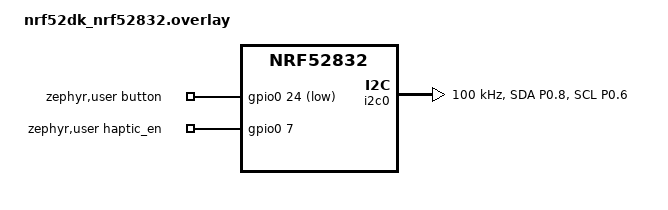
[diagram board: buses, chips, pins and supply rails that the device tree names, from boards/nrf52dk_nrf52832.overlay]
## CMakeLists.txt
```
cmake_minimum_required(VERSION 3.20.0)

list(APPEND BOARD_ROOT ${CMAKE_CURRENT_SOURCE_DIR})

# Inicialize Zephyr build system
find_package(Zephyr REQUIRED HINTS $ENV{ZEPHYR_BASE})

# Project name and version
project(
    joya_phone_connection_fw
    VERSION 2.0
    DESCRIPTION "Firmware for Joya controller with modular architecture"
)

# Source files for the application
target_sources(app PRIVATE 
    src/main.c
    src/app_comm.c
    src/app_state.c
    src/ble_driver.c
    src/ota_access.c
    src/test_image_guard.c
    src/button.c
    src/haptics.c
    src/flash_memory.c
    src/emergency_phase.c
    src/diagnostics.c
    src/battery.c
    src/wdt_guard.c
    src/fatal_recovery.c
)

target_sources_ifdef(CONFIG_JOYA_HAPTICS_TEST_INDICATOR app PRIVATE
    src/haptics_test_indicator.c
)

# Include directories for the application
target_include_directories(app PRIVATE include)
```

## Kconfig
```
mainmenu "Joya firmware"

source "Kconfig.zephyr"

config JOYA_HAPTICS_TEST_INDICATOR
	bool "Show allowed haptic requests on nRF52 DK LED0"
	default n
	depends on BOARD_NRF52DK_NRF52832 && GPIO
	help
	  Diagnostic only. Pulse LED0 when battery policy allows a haptic
	  request, regardless of whether the physical DRV2605 is present.
```

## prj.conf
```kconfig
# ==================================================
# GPIO CORE
# ==================================================
CONFIG_GPIO=y
CONFIG_ADC=y

# ==================================================
# I2C CORE
# ==================================================
CONFIG_I2C=y

# ==================================================
# LOGGING / CONSOLE DISABLED
# ==================================================
CONFIG_LOG=n
CONFIG_PRINTK=n
CONFIG_CONSOLE=n
CONFIG_EARLY_CONSOLE=n
CONFIG_BOOT_BANNER=n

CONFIG_UART_CONSOLE=n
CONFIG_RTT_CONSOLE=n

CONFIG_LOG_BACKEND_RTT=n
CONFIG_LOG_BACKEND_UART=n

# ==================================================
# MANUAL SEGGER RTT DEBUG ONLY
# ==================================================
CONFIG_USE_SEGGER_RTT=n
CONFIG_SEGGER_RTT_MODE_NO_BLOCK_SKIP=n
CONFIG_SEGGER_RTT_INIT_MODE_ALWAYS=n

# ==================================================
# Stacks
# ==================================================
CONFIG_MAIN_STACK_SIZE=4096
CONFIG_SYSTEM_WORKQUEUE_STACK_SIZE=4096


# ==================================================
# BLUETOOTH CORE
# ==================================================
CONFIG_BT=y
CONFIG_BT_PERIPHERAL=y

# Nombre base por defecto
CONFIG_BT_DEVICE_NAME="Joya"

# Habilitar la capacidad de cambiar el nombre dinámicamente
CONFIG_BT_DEVICE_NAME_DYNAMIC=y
CONFIG_BT_DEVICE_NAME_MAX=32

CONFIG_BT_MAX_CONN=1
CONFIG_BT_GATT_DYNAMIC_DB=y

# For debug
CONFIG_BT_GAP_PERIPHERAL_PREF_PARAMS=y
CONFIG_BT_PERIPHERAL_PREF_MIN_INT=36      
# 45 ms - apple pide >= 15 ms, < 2 s (unidades de 1.25 ms)
CONFIG_BT_PERIPHERAL_PREF_MAX_INT=72      
# 90 ms - apple pide <= 2 segundos
CONFIG_BT_PERIPHERAL_PREF_LATENCY=4       
# apple pide <= 30
CONFIG_BT_PERIPHERAL_PREF_TIMEOUT=600     
# 6 s - apple pide entre 6 y 18 segundos (unidades de 10 ms)

# ==================================================
# FOR FLASH STORAGE
# ==================================================
CONFIG_FLASH=y
CONFIG_FLASH_MAP=y
CONFIG_FLASH_PAGE_LAYOUT=y
CONFIG_NVS=y

CONFIG_SETTINGS=y
CONFIG_SETTINGS_NVS=y

#CONFIG_ARM_MPU=y
CONFIG_MPU_ALLOW_FLASH_WRITE=y

# Hardware watchdog: one RR channel, active during sleep, paused by a debugger.
CONFIG_WATCHDOG=y
CONFIG_WDT_NRFX_NO_IRQ=y

# Route controller assertions through the application's fatal reset handler.
CONFIG_BT_CTLR_ASSERT_HANDLER=y

# ==================================================
# MCUboot / OTA por Bluetooth
# ==================================================
CONFIG_BOOTLOADER_MCUBOOT=y

CONFIG_FLASH=y
CONFIG_FLASH_MAP=y
CONFIG_STREAM_FLASH=y
CONFIG_IMG_MANAGER=y

CONFIG_NET_BUF=y
CONFIG_ZCBOR=y
CONFIG_CRC=y

CONFIG_MCUMGR=y
CONFIG_MCUMGR_GRP_IMG=y
CONFIG_MCUMGR_GRP_OS=y
CONFIG_MCUMGR_TRANSPORT_BT=y
CONFIG_MCUMGR_TRANSPORT_BT_DYNAMIC_SVC_REGISTRATION=y
CONFIG_MCUMGR_MGMT_NOTIFICATION_HOOKS=y
CONFIG_MCUMGR_GRP_IMG_UPLOAD_CHECK_HOOK=y
CONFIG_MCUMGR_GRP_IMG_STATUS_HOOKS=y
CONFIG_MCUMGR_GRP_IMG_SLOT_INFO=y

#CONFIG_LOG=y
#CONFIG_MCUMGR_GRP_IMG_LOG_LEVEL_DBG=y

#CONFIG_USE_SEGGER_RTT=y
#CONFIG_LOG_BACKEND_RTT=y

CONFIG_BT_L2CAP_TX_MTU=247
CONFIG_BT_BUF_ACL_RX_SIZE=251
CONFIG_BT_BUF_ACL_TX_SIZE=251
CONFIG_BT_CTLR_DATA_LENGTH_MAX=251
CONFIG_BT_BUF_ACL_TX_COUNT=3

# Test with internal RC
CONFIG_CLOCK_CONTROL_NRF_K32SRC_RC=y
CONFIG_CLOCK_CONTROL_NRF_K32SRC_XTAL=n
CONFIG_CLOCK_CONTROL_NRF_K32SRC_500PPM=y

# Power
CONFIG_PM_DEVICE=y

# ===== Soporte iBeacons
CONFIG_BT_EXT_ADV=y
CONFIG_BT_EXT_ADV_MAX_ADV_SET=2
```

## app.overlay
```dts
#include <zephyr/dt-bindings/gpio/gpio.h>
#include <zephyr/dt-bindings/i2c/i2c.h>
#include <zephyr/dt-bindings/pinctrl/nrf-pinctrl.h>

/ {
	zephyr,user {
		button_gpios = <&gpio0 24 (GPIO_PULL_UP | GPIO_ACTIVE_LOW)>;
		haptic_en_gpios = <&gpio0 7 GPIO_ACTIVE_HIGH>;
	};
};

&pinctrl {
	i2c0_default: i2c0_default {
		group1 {
			psels = <NRF_PSEL(TWIM_SDA, 0, 8)>,
				<NRF_PSEL(TWIM_SCL, 0, 6)>;
		};
	};

	i2c0_sleep: i2c0_sleep {
		group1 {
			psels = <NRF_PSEL(TWIM_SDA, 0, 8)>,
				<NRF_PSEL(TWIM_SCL, 0, 6)>;
			low-power-enable;
		};
	};
};

&i2c0 {
	status = "okay";
	clock-frequency = <I2C_BITRATE_STANDARD>;
	pinctrl-0 = <&i2c0_default>;
	pinctrl-1 = <&i2c0_sleep>;
	pinctrl-names = "default", "sleep";
};

&uart0 {
	status = "disabled";
};
```

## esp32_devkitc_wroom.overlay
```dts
/ {
    aliases {
        boton-emergencia = &boton_esp;
    };

    /* Define button node */
    botones_joya {
        compatible = "gpio-keys";

        boton_esp: boton_0 {
            gpios = <&gpio0 0 (GPIO_PULL_UP | GPIO_ACTIVE_LOW)>;
            label = "Test Button ESP32";
        };
    };

    /* For printk */
    chosen {
        zephyr,console = &uart0;
        zephyr,shell-uart = &uart0;
    };
};

/* Serial port 0 - 115200 */
&uart0 {
    status = "okay";
    current-speed = <115200>;
};
```

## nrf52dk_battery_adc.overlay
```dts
/* Test fixture: connect the battery divider output to DK A5 / P0.31.
 * The firmware expects the same 120k/82k divider used by Joya.
 */
#include <zephyr/dt-bindings/adc/adc.h>
#include <zephyr/dt-bindings/adc/nrf-adc.h>

/ {
	zephyr,user {
		io-channels = <&adc 0>;
		io-channel-names = "battery";
	};
};

&adc {
	status = "okay";
	#address-cells = <1>;
	#size-cells = <0>;

	channel@0 {
		reg = <0>;
		zephyr,gain = "ADC_GAIN_1_3";
		zephyr,reference = "ADC_REF_INTERNAL";
		zephyr,acquisition-time = <ADC_ACQ_TIME(ADC_ACQ_TIME_MICROSECONDS, 40)>;
		zephyr,input-positive = <NRF_SAADC_AIN7>;
		zephyr,resolution = <12>;
	};
};
```

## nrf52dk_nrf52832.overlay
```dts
#include <zephyr/dt-bindings/gpio/gpio.h>
#include <zephyr/dt-bindings/i2c/i2c.h>
#include <zephyr/dt-bindings/pinctrl/nrf-pinctrl.h>

/ {
	/*
 	* NOTE:
 	* This configuration uses the nRF52 DK user button (P0.13).
 	* When running on the target hardware, replace the GPIO
 	* below with the pin connected to the emergency button.
 	*/

	joya_buttons {
		compatible = "gpio-keys";

		emergency_button: emergency_button {
			gpios = <&gpio0 14 (GPIO_PULL_UP | GPIO_ACTIVE_LOW)>;
			label = "Joya emergency button";
			zephyr,code = <INPUT_KEY_0>;
		};
	};

	zephyr,user {
		haptic_en_gpios = <&gpio0 7 GPIO_ACTIVE_HIGH>;
	};

	aliases {
		boton-emergencia = &emergency_button;
	};
};

&pinctrl {
	i2c0_default: i2c0_default {
		group1 {
			psels = <NRF_PSEL(TWIM_SDA, 0, 8)>,
				<NRF_PSEL(TWIM_SCL, 0, 6)>;
		};
	};

	i2c0_sleep: i2c0_sleep {
		group1 {
			psels = <NRF_PSEL(TWIM_SDA, 0, 8)>,
				<NRF_PSEL(TWIM_SCL, 0, 6)>;
			low-power-enable;
		};
	};
};

&i2c0 {
	status = "okay";
	clock-frequency = <I2C_BITRATE_STANDARD>;
	pinctrl-0 = <&i2c0_default>;
	pinctrl-1 = <&i2c0_sleep>;
	pinctrl-names = "default", "sleep";
};

&uart0 {
	status = "disabled";
};

&uicr {
    /delete-property/ gpio-as-nreset;
};
```

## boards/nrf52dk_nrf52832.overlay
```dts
#include <zephyr/dt-bindings/gpio/gpio.h>
#include <zephyr/dt-bindings/i2c/i2c.h>
#include <zephyr/dt-bindings/pinctrl/nrf-pinctrl.h>

/ {
	zephyr,user {
		button-gpios = <&gpio0 24 (GPIO_PULL_UP | GPIO_ACTIVE_LOW)>;
		haptic_en-gpios = <&gpio0 7 GPIO_ACTIVE_HIGH>;
	};
};

&pinctrl {
	i2c0_default: i2c0_default {
		group1 {
			psels = <NRF_PSEL(TWIM_SDA, 0, 8)>,
				<NRF_PSEL(TWIM_SCL, 0, 6)>;
		};
	};

	i2c0_sleep: i2c0_sleep {
		group1 {
			psels = <NRF_PSEL(TWIM_SDA, 0, 8)>,
				<NRF_PSEL(TWIM_SCL, 0, 6)>;
			low-power-enable;
		};
	};
};

&i2c0 {
	status = "okay";
	clock-frequency = <I2C_BITRATE_STANDARD>;
	pinctrl-0 = <&i2c0_default>;
	pinctrl-1 = <&i2c0_sleep>;
	pinctrl-names = "default", "sleep";

	/* (to do) add haptic driver */
};

&uart0 {
	status = "disabled";
};

// Just for solve the warning of using GPIO0_24
&spi2 {
        status = "disabled";
};
```

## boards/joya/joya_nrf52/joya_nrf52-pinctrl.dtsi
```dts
#include <zephyr/dt-bindings/pinctrl/nrf-pinctrl.h>

&pinctrl {
	i2c0_default: i2c0_default {
		group1 {
			psels = <NRF_PSEL(TWIM_SDA, 0, 8)>,
				<NRF_PSEL(TWIM_SCL, 0, 6)>;

			// Remove internal pull-up resistor
		};
	};

	i2c0_sleep: i2c0_sleep {
		group1 {
			psels = <NRF_PSEL(TWIM_SDA, 0, 8)>,
				<NRF_PSEL(TWIM_SCL, 0, 6)>;
			low-power-enable;
		};
	};
};
```

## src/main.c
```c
#include <zephyr/kernel.h>
#include <zephyr/dfu/mcuboot.h>
#include <zephyr/sys/reboot.h>
#include "button.h"
#include "app_state.h"
#include "battery.h"
#include "test_image_guard.h"
#include "diagnostics.h"
#include "wdt_guard.h"

int main(void) {
    bool watchdog_active = wdt_guard_init();
    bool ota_test_boot = !boot_is_img_confirmed();

    int ret ;
    ret = storage_init();
    diagnostics_record_init(DIAG_INIT_SETTINGS, ret);
    if (ret != 0) {
        // Storage initialization failed - continuing with RAM defaults
    }
    
    if (ota_test_boot) {
        /* A Test image must prove the recovery button and BLE setup path work. */
        test_image_guard_init();
        ret = button_init();
        diagnostics_record_init(DIAG_INIT_BUTTON, ret);
        if (ret != 0) {
            sys_reboot(SYS_REBOOT_COLD);
        }
        ret = ble_driver_init();
        diagnostics_record_init(DIAG_INIT_BLE, ret);
        if (ret != 0) {
            sys_reboot(SYS_REBOOT_COLD);
        }
        ret = app_start_test_setup();
        if (ret != 0) {
            sys_reboot(SYS_REBOOT_COLD);
        }
        test_image_guard_start();
    } else {
        ret = ble_driver_init();
        diagnostics_record_init(DIAG_INIT_BLE, ret);
        if (ret != 0) {
            /* The guard never feeds before main_ready. With WDT running,
             * sleep until its hardware reset; otherwise retry after a delay.
             */
            if (!watchdog_active) {
                k_sleep(K_SECONDS(30));
                sys_reboot(SYS_REBOOT_COLD);
            }
            k_sleep(K_FOREVER);
        }
        ret = button_init();
        diagnostics_record_init(DIAG_INIT_BUTTON, ret);
        if (ret != 0) {
            /* BLE is initialized; continue without button gestures. */
        }
    }


    ret = haptics_init();
    diagnostics_record_init(DIAG_INIT_HAPTIC, ret);
    if (ret < 0) {
        // LOG: Haptics initialization failed - continuing without haptics
        // (improvement): decide what to do if haptics initialization fails (e.g., retry, log error, etc.)
    } 
    
    /*else {
         * Non-blocking startup check. If the haptic controller was detected,
         * schedule one short existing pattern without delaying BLE or OTA.
         
        haptics_play(HAPTICS_PATTERN_ACK_CONNECTION);
    }
    */

    ret = battery_init();
    if (ret == 0) {
        ret = battery_monitor_start();
    }
    diagnostics_record_init(DIAG_INIT_BATTERY, ret);
    diagnostics_finish_init();
    wdt_guard_main_ready();
    
    // LOG: Initialization complete


    // Keep the main thread alive
    k_sleep(K_FOREVER);
}
```

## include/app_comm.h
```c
#ifndef APP_COMM_H
#define APP_COMM_H

#include <stdint.h>
#include <stddef.h>
#include <sys/types.h>
#include <zephyr/bluetooth/conn.h>
#include <zephyr/bluetooth/gatt.h>
#include "app_state.h"

/**
 * @brief Save the received application identifier.
 * @return 0 on success, non-zero on failure.
 */
int save_received_app_id(const uint8_t *received_app_id);

/**
 * @brief Compare the saved application identifier with the received identifier.
 * @param saved_app_id Pointer to the saved application identifier to compare.
 * @return 0 if the identifiers match, or a non-zero value otherwise.
 */
int check_app_id(const uint8_t *received_app_id, const uint8_t *saved_app_id);

/**
 * @brief Handle writes to the RX characteristic.
 * @param conn The Bluetooth connection.
 * @param attr The GATT attribute.
 * @param buf Buffer containing the received data.
 * @param len Length of the received data.
 * @param offset Offset of the received data.
 * @param flags Write flags.
 * @return The number of bytes processed, or a GATT error.
 */
ssize_t on_rx_write_handler(struct bt_conn *conn, const struct bt_gatt_attr *attr, const void *buf, uint16_t len, uint16_t offset, uint8_t flags);

/**
 * @brief Handle BLE connection events.
 * @param conn The Bluetooth connection.
 * @param err Connection error code.
 */
void on_connected_handler(struct bt_conn *conn, uint8_t err);

/**
 * @brief Handle BLE disconnection events.
 * @param conn The Bluetooth connection.
 * @param reason Disconnection reason code.
 */
void on_disconnected_handler(struct bt_conn *conn, uint8_t reason);

/**
 * @brief Handle writes to the RX authentication characteristic.
 * @param conn The Bluetooth connection.
 * @param attr The GATT attribute.
 * @param buf Buffer containing the received application identifier.
 * @param len Length of the received data.
 * @param offset Offset of the received data.
 * @param flags Write flags.
 * @return The number of bytes processed, or a GATT error.
 */
ssize_t on_rx_auth_write_handler(struct bt_conn *conn, const struct bt_gatt_attr *attr, const void *buf, uint16_t len, uint16_t offset, uint8_t flags);

/** @brief Application command enumeration. 
*/
enum {
    INIT_JOYA_COMMAND = 0x01,
    COMMAND_ROUTINE = 0x02,
    COMMAND_END_ROUTINE = 0x03,
    COMMAND_EMERGENCY = 0x04,
    COMMAND_ACK = 0x05,
    COMMAND_NACK = 0x06,
    LOW_BATTERY_LEVEL_1 = 0x07,
    LOW_BATTERY_LEVEL_2 = 0x08,
    BATTERY_NORMAL = 0x09,
    END_JOYA_COMMAND = 0x0A,

    INIT_APP_COMMAND = 0x40,
    COMMAND_ACK_EMERGENCY = 0x41,
    COMMAND_STOP_EMERGENCY = 0x42,
    COMMAND_FOLLOW_ME = 0x43,
    COMMAND_FRIEND_EMERGENCY = 0x44,
    COMMAND_FRIEND_STOP_EMERGENCY = 0x45,
    END_APP_COMMAND = 0x46,
    COMMAND_OTA_ENABLE = 0x70,
    COMMAND_OTA_DISABLE = 0x71,
};

#endif
```

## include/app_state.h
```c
#ifndef APP_STATE_H
#define APP_STATE_H

#define SIZE_APP_ID 16

#include "ble_driver.h"
#include "app_comm.h"
#include "flash_memory.h"
#include "haptics.h"

#include <stdbool.h>
#include <stdint.h>
#include <zephyr/kernel.h>

#define EMERGENCY_RETRY_INITIAL_MS 1000
#define EMERGENCY_RETRY_FAST_MS 2000
#define EMERGENCY_RETRY_MEDIUM_MS 5000
#define EMERGENCY_RETRY_SLOW_MS 10000
#define EMERGENCY_RETRY_VERY_SLOW_MS 30000

#define BLE_SETUP_TIMEOUT_MS 90000

typedef enum {
    STATE_UNPAIRED,
    STATE_SETUP_MODE,
    STATE_SETUP_WAITING_IDENTIFIER,
    STATE_SETUP_WAITING_NEW_IDENTIFIER,
    STATE_WAITING_NOTIFICATION_ENABLE,
    STATE_BONDED_DISCONNECTED,
    STATE_AUTHENTICATED,
    STATE_EMERGENCY
} app_state_t;

typedef enum {
    // BUTTON EVENTS
    EV_BTN_1_PULSE,
    EV_BTN_2_PULSE,
    EV_BTN_LONG_PRESS,  
    EV_BTN_FACTORY_THRESHOLD,
    EV_BTN_SUSPEND_REQUEST,
    EV_BTN_EMERGENCY,   
    EV_BTN_FACTORY_RESET,
    EV_BOOT_TEST_SETUP_REQUEST,

    // JOYA EVENTS
    EV_APP_IDENTIFIER_RECEIVED,
    EV_EMERGENCY_RETRY,
    EV_BATTERY_LEVEL_1,
    EV_BATTERY_LEVEL_2,
    EV_BATTERY_NORMAL,
    EV_BATTERY_RECHECK_DONE,
    EV_CRITICAL_WINDOW_TIMEOUT,
    
    // CONNECTION EVENTS
    EV_BLE_CONNECTED,
    EV_BLE_DISCONNECTED,
    EV_BLE_TIMEOUT,
    EV_BLE_RESTART_ADVERTISING,
    EV_BLE_NOTIFY_ENABLED,
    EV_BLE_BATTERY_NOTIFY_ENABLED,
    EV_AUTH_DELIVERY_RETRY,

    // APPLICATION EVENTS
    EV_APP_STOP_EMERGENCY,     
    EV_APP_FOLLOW_ME,
    EV_APP_ACK_EMERGENCY,
    EV_APP_FRIEND_EMERGENCY,
    EV_APP_OTA_ENABLE,
    EV_APP_OTA_DISABLE,
    EV_OTA_UPDATE_STOPPED,
    EV_HAPTICS_SUSPEND_DONE,
    EV_HAPTICS_FACTORY_DONE
} event_type_t;

typedef struct {
    event_type_t type;
    struct bt_conn *conn;
    uint8_t app_id[SIZE_APP_ID];
} app_event_t;

/**
 * @brief Process an application event.
 * @param event The event to process.
 */
void process_event(const app_event_t *entry);

/**
 * @brief Run the finite state machine thread loop.
 * This function initializes the work structures and enters the main event loop.
 */
void fsm_thread_loop(void);

/**
 * @brief Add an event to the event queue.
 * @param event The event to add.
 * @return 0 on success, or a negative error code on failure.
 */
int add_event(event_type_t event);
int add_event_for_conn(event_type_t event, struct bt_conn *conn, const uint8_t *app_id);

/** Number of events waiting for the FSM thread. */
unsigned int app_state_pending_events(void);

/**
 * @brief Get the current application state.
 * @return The current application state.
 */
app_state_t get_current_state(void);

/** Start Setup Mode from the FSM for an MCUboot Test image and report advertising status. */
int app_start_test_setup(void);

#endif // APP_STATE_H
```

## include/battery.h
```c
#ifndef JOYA_BATTERY_H_
#define JOYA_BATTERY_H_

#include <stdint.h>

#define BATTERY_MONITOR_INTERVAL_MS     60000
#define BATTERY_VERIFY_INTERVAL_MS      10000
#define BATTERY_VERIFY_SAMPLES          6
#define BATTERY_VERIFY_MIN_VOTES        5
#define BATTERY_RECHECK_INTERVAL_MS     1000

#define BATTERY_LEVEL_1_MV              3000//3500
#define BATTERY_LEVEL_2_MV              2900//3400

/* Para recuperarse, cada umbral exige superar su valor por este margen. */
#define BATTERY_HYSTERESIS_MV           50

/* Inicializar el canal SAADC antes de leer o iniciar el monitoreo. */
int battery_init(void);

/* Leer VBAT en milivoltios. Esta llamada espera a que termine una conversión. */
int battery_get_voltage_mv(int32_t *voltage_mv);

/* Programar la primera medición de inmediato y luego cada intervalo. */
int battery_monitor_start(void);
int battery_monitor_stop(void);

/* Devuelve -ENODATA hasta la primera medición periódica exitosa. */
int battery_get_last_voltage_mv(int32_t *voltage_mv);

/* Request six fresh ADC samples; completion arrives as EV_BATTERY_RECHECK_DONE. */
int battery_request_recheck(void);
/* Return the verified level (0/1/2), or -ENODATA without five valid samples. */
int battery_get_recheck_level(void);

#endif /* JOYA_BATTERY_H_ */
```

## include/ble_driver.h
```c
#ifndef BLE_DRIVER_H
#define BLE_DRIVER_H

#include <stdint.h>
#include <zephyr/kernel.h>
#include <zephyr/bluetooth/bluetooth.h>
#include <zephyr/bluetooth/uuid.h>
#include <zephyr/bluetooth/gatt.h>
#include "ibeacon_policy.h"
#include "app_state.h"
#include "app_comm.h"

// --- UUIDs of JOYA custom service ---
// Main service UUID

// JOYA COMMANDS SERVICE
#define BT_UUID_JOYA_COMMANDS_SERVICE_VAL       BT_UUID_128_ENCODE(0xa407e00a, 0x00c1, 0x464d, 0x9173, 0x2cb8be585000)
#define BT_UUID_JOYA_TX_VAL                     BT_UUID_128_ENCODE(0xa407e00a, 0x00c1, 0x464d, 0x9173, 0x2cb8be585001)
#define BT_UUID_JOYA_RX_VAL                     BT_UUID_128_ENCODE(0xa407e00a, 0x00c1, 0x464d, 0x9173, 0x2cb8be585002)

// JOYA AUTHENTICATION SERVICE
#define BT_UUID_JOYA_AUTH_SERVICE_VAL           BT_UUID_128_ENCODE(0xa407e00a, 0x00c1, 0x464d, 0x9173, 0x2cb8be585100)
#define BT_UUID_JOYA_RX_AUTH_VAL                BT_UUID_128_ENCODE(0xa407e00a, 0x00c1, 0x464d, 0x9173, 0x2cb8be585101)

// JOYA CONFIGURATION SERVICE
#define BT_UUID_JOYA_CONFIG_SERVICE_VAL         BT_UUID_128_ENCODE(0xa407e00a, 0x00c1, 0x464d, 0x9173, 0x2cb8be585200)
#define BT_UUID_JOYA_NAME_VAL                   BT_UUID_128_ENCODE(0xa407e00a, 0x00c1, 0x464d, 0x9173, 0x2cb8be585201)
#define BT_UUID_JOYA_DIAGNOSTICS_VAL            BT_UUID_128_ENCODE(0xa407e00a, 0x00c1, 0x464d, 0x9173, 0x2cb8be585202)

// JOYA BATTERY SERVICE: change = 0/1/2; measurement = battery voltage in mV
#define BT_UUID_JOYA_BATTERY_SERVICE_VAL        BT_UUID_128_ENCODE(0xa407e00a, 0x00c1, 0x464d, 0x9173, 0x2cb8be585300)
#define BT_UUID_JOYA_BATTERY_CHANGE_VAL         BT_UUID_128_ENCODE(0xa407e00a, 0x00c1, 0x464d, 0x9173, 0x2cb8be585301)
#define BT_UUID_JOYA_BATTERY_MEASUREMENT_VAL    BT_UUID_128_ENCODE(0xa407e00a, 0x00c1, 0x464d, 0x9173, 0x2cb8be585302)

// JOYA IBEACON: manufacturer data uses UUID bytes in displayed (network) order.
// BT_UUID_128_ENCODE() uses the reversed byte order required by Zephyr BLE UUIDs.
#define JOYA_IBEACON_CONNECTION_UUID_BYTES \
    0xa4, 0x07, 0xe0, 0x0a, 0x00, 0xc1, 0x46, 0x4d, \
    0x91, 0x73, 0x2c, 0xb8, 0xbe, 0x58, 0x60, 0x01

/**
 * @brief Initialize the Bluetooth stack.
 * @return 0 on success, or a negative error code on failure.
 */
int ble_driver_init(void);
bool ble_is_current_conn(struct bt_conn *conn);
bool ble_has_connection(void);
bool ble_is_authenticated_conn(struct bt_conn *conn);
bool ble_mark_authenticated_conn(struct bt_conn *conn);
bool ble_commands_subscribed_for_conn(struct bt_conn *conn);
/* Diagnostics transport: zero means no authenticated subscribed session. */
uint32_t ble_diagnostics_session(void);
void ble_diagnostics_notify_for_session(uint32_t session,
                                        const uint8_t *data, uint16_t len);

/* Used for the authentication ACK/NACK on the connection that supplied APP_ID. */
int ble_send_event_for_conn(struct bt_conn *conn, uint8_t event_byte);
/* Only sends on the currently authenticated, subscribed connection. */
int ble_send_event_authenticated(uint8_t event_byte);

/** Notify the confirmed battery level on the change characteristic. */
int ble_send_battery_change(uint8_t level);

/** Notify battery voltage in mV as an unsigned 16-bit little-endian value. */
int ble_send_battery_measurement(int32_t voltage_mv);

/**
 * @brief Start advertising for a new connection or reconnection.
 * @param is_new_connection Set to true for new connections (JOYA SETUP), false for reconnections (JOYA).
 * @return 0 on success, or a negative error code on failure.
 */
int ble_start_setup_advertising(bool is_new_connection);

/* Runs the connection iBeacon only while connectable advertising is active. */
int ble_set_ibeacon_mode(ble_ibeacon_mode_t mode);


/**
 * @brief Stop any ongoing advertising.
 * @return 0 on success, or a negative error code on failure.
 */
int ble_stop_advertising(void);

/**
 * @brief Force a Bluetooth disconnection and stop advertising.
 * @return 0 on success, or a negative error code on failure.
 */
int ble_disconnect(void);

int ble_start_setup_advertising_backup(void);

#endif // BLE_DRIVER_H
```

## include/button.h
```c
#ifndef BUTTON_H
#define BUTTON_H

#include <stdint.h>
#include <zephyr/kernel.h>
#include <zephyr/device.h>
#include <zephyr/drivers/gpio.h>
#include "app_state.h"

extern struct k_msgq event_queue;

#define DEBOUNTE_TIME_MS 50
#define CLICK_WINDOW_MS 900
#define BUTTON_ROUTINE_CANCEL_HOLD_MS 500
#define BUTTON_SUSPEND_HOLD_MS 5000 /* action on release, before factory threshold */
#define BUTTON_FACTORY_RESET_HOLD_MS 15000

/**
 * @brief Initialize the button GPIO and interrupt handling.
 * @return 0 on success, or a negative error code on failure.
 */
int button_init(void);

/**
 * @brief Handle button GPIO interrupts.
 * @param dev GPIO device that generated the interrupt.
 * @param cb GPIO callback data.
 * @param pins GPIO pins that generated the interrupt.
 */
void button_isr_handler(const struct device *dev, struct gpio_callback *cb, uint32_t pins);

#endif // BUTTON_H
```

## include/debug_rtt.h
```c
#pragma once

#include <zephyr/kernel.h>

#if IS_ENABLED(CONFIG_USE_SEGGER_RTT)
#include <SEGGER_RTT.h>

static inline void dbg_rtt_mark(const char *msg)
{
    SEGGER_RTT_WriteString(0, msg);
}

#else

static inline void dbg_rtt_mark(const char *msg)
{
    ARG_UNUSED(msg);
}

#endif
```

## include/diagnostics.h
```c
#ifndef DIAGNOSTICS_H
#define DIAGNOSTICS_H

#include <stdint.h>

#define DIAG_INIT_BLE       (1u << 0)
#define DIAG_INIT_BUTTON    (1u << 1)
#define DIAG_INIT_SETTINGS  (1u << 2)
#define DIAG_INIT_HAPTIC    (1u << 3)
#define DIAG_INIT_BATTERY   (1u << 4)

typedef enum {
    DIAG_ERROR_FLASH_WRITE = 0xE1,
    DIAG_ERROR_SETTINGS_LOAD = 0xE2,
    DIAG_ERROR_EVENT_QUEUE_FULL = 0xE3,
    DIAG_ERROR_BLE = 0xE4,
    DIAG_ERROR_I2C = 0xE5,
} diagnostics_error_t;

void diagnostics_record_init(uint8_t bit, int result);
void diagnostics_finish_init(void);
void diagnostics_get_init_message(uint8_t out[2]);
void diagnostics_request_init_notification(void);
void diagnostics_report_error(diagnostics_error_t error);

#endif
```

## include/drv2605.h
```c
#ifndef DRV2605_H
#define DRV2605_H

#include <stdbool.h>
#include <stdint.h>

/**
 * @brief Initialize the DRV2605 controller.
 * @return 0 on success, or a negative error code on failure.
 */
int drv2605_init(void);

/**
 * @brief Set real-time playback mode and apply an amplitude.
 * @param amplitude Real-time playback amplitude to apply.
 * @return 0 on success, or a negative error code on failure.
 */
int drv2605_set_rtp(uint8_t amplitude);

/**
 * @brief Stop real-time playback and return to internal trigger mode.
 * @return 0 on success, or a negative error code on failure.
 */
int drv2605_stop(void);

/**
 * @brief Check whether the DRV2605 was initialized successfully.
 * @return true if the controller is ready, otherwise false.
 */
bool drv2605_is_ready(void);

#endif /* DRV2605_H */
```

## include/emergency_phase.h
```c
#ifndef EMERGENCY_PHASE_H
#define EMERGENCY_PHASE_H

#include <stdbool.h>
#include <stdint.h>

/* Values 0 and 1 match the bool stored by older firmware. */
typedef enum {
    EMERGENCY_NONE = 0,
    EMERGENCY_PENDING_ACK = 1,
    EMERGENCY_ACKED = 2,
} emergency_phase_t;

typedef enum {
    EMERGENCY_TRIGGER,
    EMERGENCY_ACK,
    EMERGENCY_STOP,
} emergency_action_t;

emergency_phase_t emergency_phase_transition(emergency_phase_t phase,
                                             emergency_action_t action);
bool emergency_phase_decode(uint8_t stored, emergency_phase_t *phase);
bool emergency_phase_needs_notification(emergency_phase_t phase);

#endif
```

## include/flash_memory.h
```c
#ifndef FLASH_MEMORY_H
#define FLASH_MEMORY_H

#include <stdint.h>
#include <stdbool.h>
#include <stddef.h>
#include <string.h>
#include "app_comm.h"
#include "emergency_phase.h"

#include <zephyr/settings/settings.h>

#define JOYA_ADV_NAME_DEFAULT "Joya"
#define JOYA_NAME_PREFIX      "Joya de "
#define JOYA_NAME_MAX_LEN     31


const char *storage_get_name(void);
int storage_save_name(const char *name);

/**
 * @brief Initialize storage and load saved settings.
 * @return 0 on success, or a non-zero value on failure.
 */
int storage_init(void);

/**
 * @brief Save the application identifier to storage.
 * @param new_app_id Pointer to the application identifier buffer.
 * @return 0 on success, or a non-zero value on failure.
 */
int storage_save_app_id(const uint8_t* new_app_id);

/**
 * @brief Clear stored application data and reset cached values.
 * @return 0 on success, or a non-zero value on failure.
 */
int storage_factory_reset(void);

/** Update the emergency phase in RAM and persist it when flash is available. */
int storage_save_emergency_phase(emergency_phase_t phase);
emergency_phase_t storage_get_emergency_phase(void);
uint8_t storage_get_pending_routine(void);
/* RAM changes first. Return 1 when the flash update fails. */
int storage_save_pending_routine(uint8_t command);

/**
 * @brief Check whether emergency mode is active.
 * @return true if emergency mode is active, false otherwise.
 */
bool is_in_emergency(void);

/**
 * @brief Check whether the application identifier is empty.
 * @return true if the application identifier is empty, false otherwise.
 */
bool is_app_id_empty(void);

/**
 * @brief Get the stored application identifier.
 * @return Pointer to the application identifier buffer.
 */
const uint8_t* storage_get_app_id(void);

#endif
```

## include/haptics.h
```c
#ifndef HAPTICS_H
#define HAPTICS_H

#include <zephyr/device.h>
#include <zephyr/drivers/gpio.h>
#include <zephyr/drivers/i2c.h>
#include <zephyr/kernel.h>
#include <errno.h>

#define DRV2605_I2C_ADDR_LOW			0x5A
#define DRV2605_I2C_ADDR_HIGH			0x5B

#define DRV2605_REG_STATUS				0x00
#define DRV2605_REG_MODE				0x01
#define DRV2605_REG_RTP_INPUT			0x02
#define DRV2605_REG_LIBRARY				0x03
#define DRV2605_REG_WAVESEQ1			0x04
#define DRV2605_REG_WAVESEQ2			0x05
#define DRV2605_REG_GO					0x0C

#define DRV2605_MODE_INTERNAL_TRIGGER	0x00
#define DRV2605_MODE_RTP				0x05
#define DRV2605_MODE_STANDBY			0x40

#define HAPTIC_RTP_OFF					0
#define HAPTIC_RTP_MAX					127

// Adaptación nuevo motor
#define DRV2605_REG_OD_CLAMP    		0x17
#define DRV2605_OD_CLAMP_2V5   			0x72
// OD_CLAMP = V_RATED/0.02196 = 2.5/0.02196 = 113.8 approx 0x72

#define HAPTIC_RTP_INTENSITY   			100
#define DRV2605_REG_FEEDBACK_CONTROL   0x1A
#define DRV2605_REG_CONTROL3           0x1D

#define DRV2605_N_ERM_LRA             BIT(7)
#define DRV2605_ERM_OPEN_LOOP         BIT(5)
#define DRV2605_DATA_FORMAT_RTP       BIT(3)

enum haptics_pattern {
	HAPTICS_PATTERN_NONE = 0,
	HAPTICS_PATTERN_SETUP_MODE,
	HAPTICS_PATTERN_ROUTINE_START,
	HAPTICS_PATTERN_ROUTINE_CANCEL,
	HAPTICS_PATTERN_EMERGENCY_START,
	HAPTICS_PATTERN_FOLLOW_ME,
    HAPTICS_PATTERN_FRIEND_EMERGENCY,
	HAPTICS_PATTERN_SUSPEND,
	HAPTICS_PATTERN_FACTORY_RESET,
	HAPTICS_PATTERN_ACK_CONNECTION,
};

enum haptics_effect {
    HAPTICS_EFFECT_AUTH = 0x01,
    HAPTICS_EFFECT_RESET = 0x2F,
};

/**
 * @brief Initialize the haptic driver.
 * @return 0 on success, or a negative error code on failure.
 */
int haptics_init(void);

/**
 * @brief Stop the active haptic pattern or effect.
 */
void haptics_stop(void);
/* Stop playback and prevent or allow all future patterns and effects. */
void haptics_set_allowed(bool allowed);

/**
 * @brief Check whether the haptic driver is ready.
 * @return true if the haptic driver is ready, false otherwise.
 */
bool haptics_is_ready(void);

/**
 * @brief Play a haptic pattern.
 * @param pattern The haptic pattern to play.
 */
void haptics_play(enum haptics_pattern pattern);

/** Start a pattern and notify from the haptics work item when its final step ends. */
int haptics_play_with_completion(enum haptics_pattern pattern,
				 void (*completion)(void));

/**
 * @brief Play one haptic effect.
 * @param effect The haptic effect to play.
 */
void haptics_play_effect(enum haptics_effect effect);

#endif /* HAPTICS_H */
```

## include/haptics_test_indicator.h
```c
#ifndef JOYA_HAPTICS_TEST_INDICATOR_H_
#define JOYA_HAPTICS_TEST_INDICATOR_H_

#if defined(CONFIG_JOYA_HAPTICS_TEST_INDICATOR)
#include <stdbool.h>
void haptics_test_indicator_request(bool battery_allows);
#else
#define haptics_test_indicator_request(battery_allows) do { } while (0)
#endif

#endif /* JOYA_HAPTICS_TEST_INDICATOR_H_ */
```
